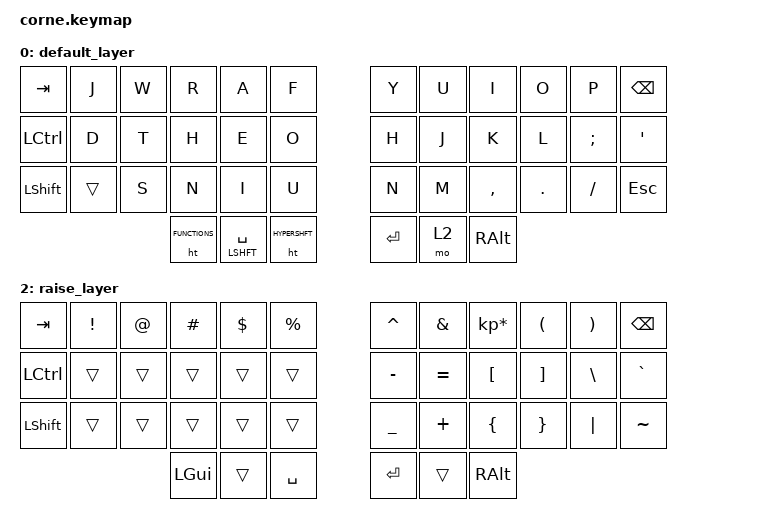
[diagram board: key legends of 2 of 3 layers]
/*
 * Copyright (c) 2020 The ZMK Contributors
 *
 * SPDX-License-Identifier: MIT
 */

#include <behaviors.dtsi>
#include <dt-bindings/zmk/keys.h>
#include <dt-bindings/zmk/bt.h>

#DEFINE MAIN 0
#DEFINE HYPERSHFT 1
#DEFINE FUNCTIONS 2

/ {
        keymap {
                compatible = "zmk,keymap";

                default_layer {
// -----------------------------------------------------------------------------------------
// |  TAB |  J  |  W  |  R  |  A  |  F  |   |    |     |    |    |    | BKSP |
// | CTRL |  D  |  T  |  H  |  E  |  O  |   |    |     |    |    |  ;  |  '   |
// | SHFT |    |  S  |  N  |  I  |  U  |   |    |     |  ,  |  .  |  /  | ESC  |
//                    | GUI | LWR | SPC |   | ENT | RSE  | ALT |
                        bindings = <
   &kp TAB   &kp J &kp W &kp R &kp A &kp F   &kp Y &kp U  &kp I     &kp O   &kp P    &kp BSPC
   &kp LCTRL &kp D &kp T &kp H &kp E &kp O   &kp H &kp J  &kp K     &kp L   &kp SEMI &kp SQT
   &kp LSHFT &trans  &kp S &kp N &kp I &kp U   &kp N &kp M  &kp COMMA &kp DOT &kp FSLH &kp ESC
                  &ht FUNCTIONS &lt LSHFT SPACE &ht HYPERSHFT    &kp RET &mo 2 &kp RALT
                        >;
                };
                lower_layer {
// -----------------------------------------------------------------------------------------
// |  TAB |  1  |  2  |  3  |  4  |  5  |   |  6  |  7  |  8  |  9  |  0  | BKSP |
// | BTCLR| BT1 | BT2 | BT3 | BT4 | BT5 |   | LFT | DWN |  UP | RGT |     |      |
// | SHFT |     |     |     |     |     |   |     |     |     |     |     |      |
//                    | GUI |     | SPC |   | ENT |     | ALT |
                        bindings = <
   &trans   &kp X    &kp M         &kp B       &kp '       &kp BSPC                &kp N6   &kp N7   &kp N8 &kp N9    &kp N0 &kp BSPC
   &trans   &kp V    &kp C         &kp L       &kp Z       &kp Q
   &kp LSHFT  &trans  &kp G         &kp K       &kp P       &kp Y         &trans   &trans   &trans &trans    &trans &trans
                          	        &kp LGUI     &kp SPACE      &kp       &kp RET  &trans   &kp RALT
                        >;
                };

                raise_layer {
// -----------------------------------------------------------------------------------------
// |  TAB |  !  |  @  |  #  |  $  |  %  |   |  ^  |  &  |  *  |  (  |  )  | BKSP |
// | CTRL |     |     |     |     |     |   |  -  |  =  |  [  |  ]  |  \  |  `   |
// | SHFT |     |     |     |     |     |   |  _  |  +  |  {  |  }  | "|" |  ~   |
//                    | GUI |     | SPC |   | ENT |     | ALT |
                        bindings = <
   &kp  TAB  &kp EXCL &kp AT &kp HASH &kp DLLR &kp PRCNT   &kp CARET &kp AMPS  &kp KP_MULTIPLY &kp LPAR &kp RPAR &kp BSPC
   &kp LCTRL &trans   &trans &trans   &trans   &trans      &kp MINUS &kp EQUAL &kp LBKT        &kp RBKT &kp BSLH &kp GRAVE
   &kp LSHFT &trans   &trans &trans   &trans   &trans      &kp UNDER &kp PLUS  &kp LBRC        &kp RBRC &kp PIPE &kp TILDE
                    	     &kp LGUI &trans   &kp SPACE   &kp RET   &trans    &kp RALT
                        >;
                };
        };
};
